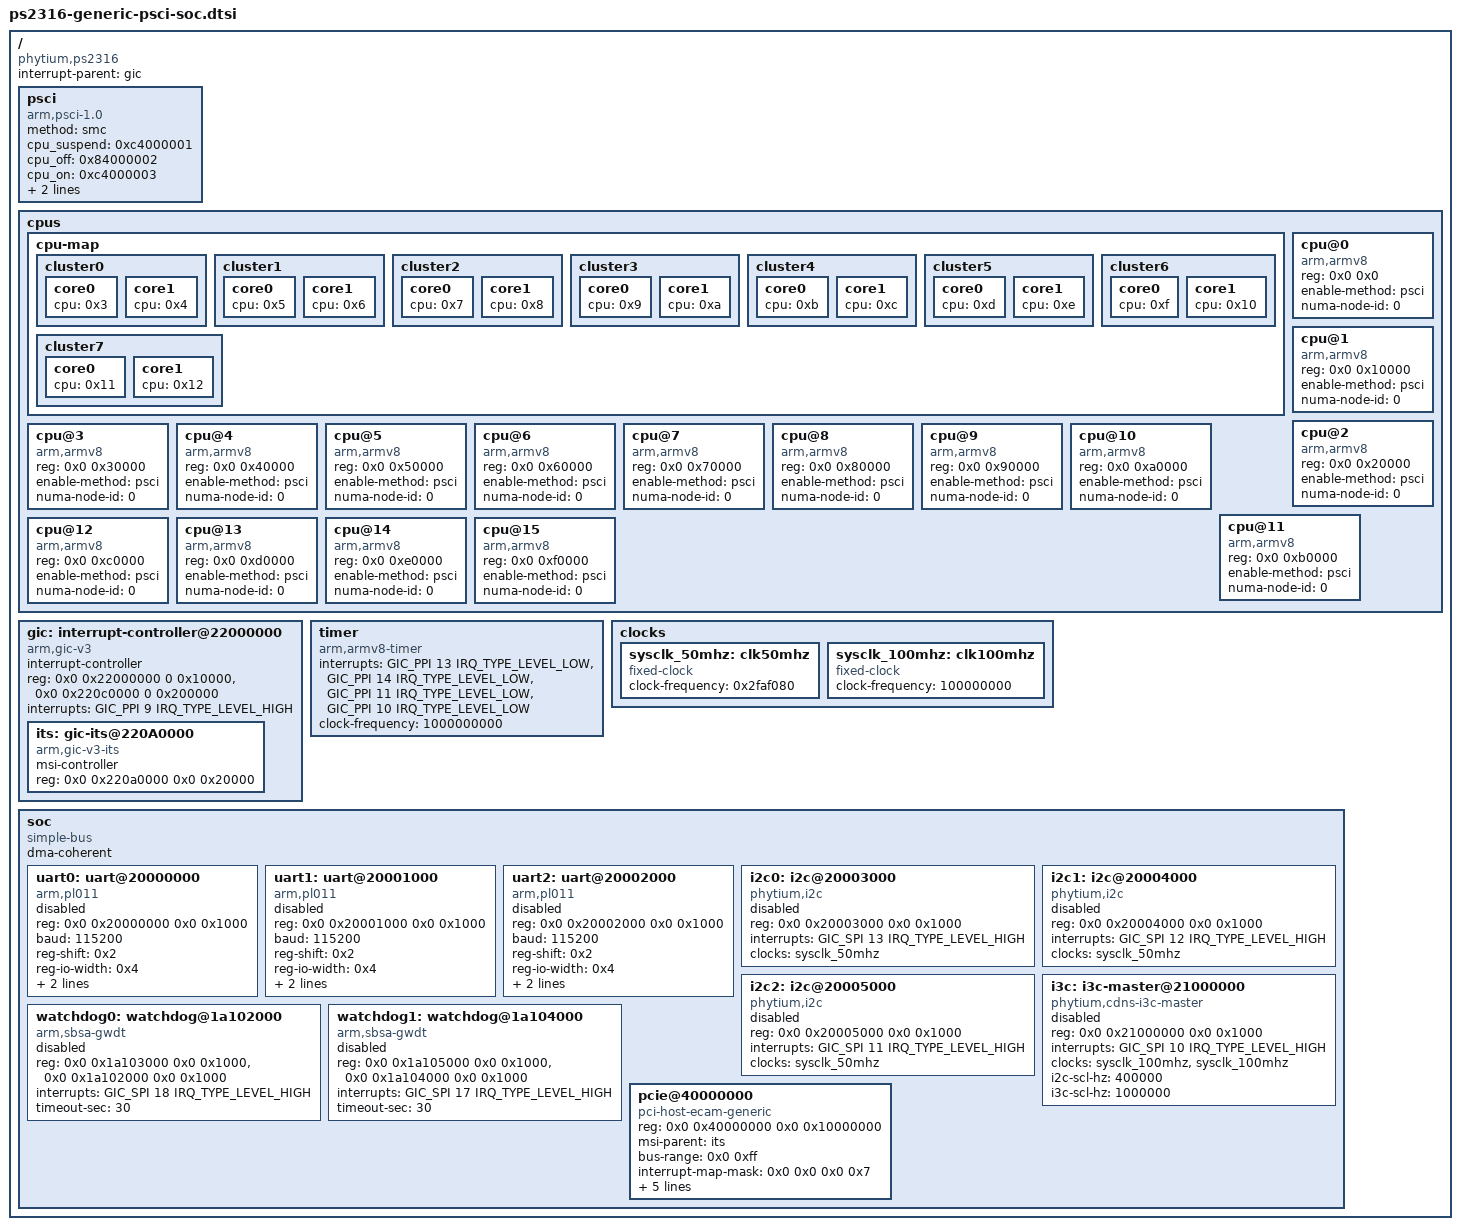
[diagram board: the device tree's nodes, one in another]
// SPDX-License-Identifier: GPL-2.0
/*
 * dts file for Phytium Ps2316 SoC
 *
 * Copyright (C) 2023, Phytium Technology Co., Ltd.
 */

#include <dt-bindings/interrupt-controller/arm-gic.h>

/ {
	compatible = "phytium,ps2316";
	interrupt-parent = <&gic>;
	#address-cells = <2>;
	#size-cells = <2>;

	psci {
		compatible   = "arm,psci-1.0";
		method       = "smc";
		cpu_suspend  = <0xc4000001>;
		cpu_off      = <0x84000002>;
		cpu_on       = <0xc4000003>;
		sys_poweroff = <0x84000008>;
		sys_reset    = <0x84000009>;
	};

	cpus {
		#address-cells = <0x2>;
		#size-cells = <0x0>;

		cpu-map {

			cluster0 {

				core0 {
					cpu = <0x3>;
				};

				core1 {
					cpu = <0x4>;
				};
			};

			cluster1 {

				core0 {
					cpu = <0x5>;
				};

				core1 {
					cpu = <0x6>;
				};
			};

			cluster2 {

				core0 {
					cpu = <0x7>;
				};

				core1 {
					cpu = <0x8>;
				};
			};

			cluster3 {

				core0 {
					cpu = <0x9>;
				};

				core1 {
					cpu = <0xa>;
				};
			};

			cluster4 {

				core0 {
					cpu = <0xb>;
				};

				core1 {
					cpu = <0xc>;
				};
			};

			cluster5 {

				core0 {
					cpu = <0xd>;
				};

				core1 {
					cpu = <0xe>;
				};
			};

			cluster6 {

				core0 {
					cpu = <0xf>;
				};

				core1 {
					cpu = <0x10>;
				};
			};

			cluster7 {

				core0 {
					cpu = <0x11>;
				};

				core1 {
					cpu = <0x12>;
				};
			};
		};

		cpu@0 {
			device_type = "cpu";
			compatible = "arm,armv8";
			reg = <0x0 0x0>;
			enable-method = "psci";
			numa-node-id = <0>;
			phandle = <0x3>;
		};

		cpu@1 {
			device_type = "cpu";
			compatible = "arm,armv8";
			reg = <0x0 0x10000>;
			enable-method = "psci";
			numa-node-id = <0>;
			phandle = <0x4>;
		};

		cpu@2 {
			device_type = "cpu";
			compatible = "arm,armv8";
			reg = <0x0 0x20000>;
			enable-method = "psci";
			numa-node-id = <0>;
			phandle = <0x5>;
		};

		cpu@3 {
			device_type = "cpu";
			compatible = "arm,armv8";
			reg = <0x0 0x30000>;
			enable-method = "psci";
			numa-node-id = <0>;
			phandle = <0x6>;
		};

		cpu@4 {
			device_type = "cpu";
			compatible = "arm,armv8";
			reg = <0x0 0x40000>;
			enable-method = "psci";
			numa-node-id = <0>;
			phandle = <0x7>;
		};

		cpu@5 {
			device_type = "cpu";
			compatible = "arm,armv8";
			reg = <0x0 0x50000>;
			enable-method = "psci";
			numa-node-id = <0>;
			phandle = <0x8>;
		};

		cpu@6 {
			device_type = "cpu";
			compatible = "arm,armv8";
			reg = <0x0 0x60000>;
			enable-method = "psci";
			numa-node-id = <0>;
			phandle = <0x9>;
		};

		cpu@7 {
			device_type = "cpu";
			compatible = "arm,armv8";
			reg = <0x0 0x70000>;
			enable-method = "psci";
			numa-node-id = <0>;
			phandle = <0xa>;
		};

		cpu@8 {
			device_type = "cpu";
			compatible = "arm,armv8";
			reg = <0x0 0x80000>;
			enable-method = "psci";
			numa-node-id = <0>;
			phandle = <0xb>;
		};

		cpu@9 {
			device_type = "cpu";
			compatible = "arm,armv8";
			reg = <0x0 0x90000>;
			enable-method = "psci";
			numa-node-id = <0>;
			phandle = <0xc>;
		};

		cpu@10 {
			device_type = "cpu";
			compatible = "arm,armv8";
			reg = <0x0 0xa0000>;
			enable-method = "psci";
			numa-node-id = <0>;
			phandle = <0xd>;
		};

		cpu@11 {
			device_type = "cpu";
			compatible = "arm,armv8";
			reg = <0x0 0xb0000>;
			enable-method = "psci";
			numa-node-id = <0>;
			phandle = <0xe>;
		};

		cpu@12 {
			device_type = "cpu";
			compatible = "arm,armv8";
			reg = <0x0 0xc0000>;
			enable-method = "psci";
			numa-node-id = <0>;
			phandle = <0xf>;
		};

		cpu@13 {
			device_type = "cpu";
			compatible = "arm,armv8";
			reg = <0x0 0xd0000>;
			enable-method = "psci";
			numa-node-id = <0>;
			phandle = <0x10>;
		};

		cpu@14 {
			device_type = "cpu";
			compatible = "arm,armv8";
			reg = <0x0 0xe0000>;
			enable-method = "psci";
			numa-node-id = <0>;
			phandle = <0x11>;
		};

		cpu@15 {
			device_type = "cpu";
			compatible = "arm,armv8";
			reg = <0x0 0xf0000>;
			enable-method = "psci";
			numa-node-id = <0>;
			phandle = <0x12>;
		};
	};

	gic: interrupt-controller@22000000 {
		compatible = "arm,gic-v3";
		#interrupt-cells = <0x3>;
		#address-cells = <0x2>;
		#size-cells = <0x2>;
		ranges;
		interrupt-controller;
		reg = <0x0 0x22000000 0 0x10000>,	/* GICD */
			<0x0 0x220c0000 0 0x200000>;	/* GICR */
		interrupts = <GIC_PPI 9 IRQ_TYPE_LEVEL_HIGH>;

		its: gic-its@220A0000 {
			compatible = "arm,gic-v3-its";
			msi-controller;
			reg = <0x0 0x220a0000 0x0 0x20000>;
		};

	};

	timer {
		compatible = "arm,armv8-timer";
		interrupts = <GIC_PPI 13 IRQ_TYPE_LEVEL_LOW>,
			     <GIC_PPI 14 IRQ_TYPE_LEVEL_LOW>,
			     <GIC_PPI 11 IRQ_TYPE_LEVEL_LOW>,
			     <GIC_PPI 10 IRQ_TYPE_LEVEL_LOW>;
		clock-frequency = <1000000000>;
	};

	clocks {
		#address-cells = <0x2>;
		#size-cells = <0x2>;
		ranges;

		sysclk_50mhz: clk50mhz {
			compatible = "fixed-clock";
			#clock-cells = <0x0>;
			clock-frequency = <0x2faf080>;
		};

		sysclk_100mhz: clk100mhz {
			compatible = "fixed-clock";
			#clock-cells = <0x0>;
			clock-frequency = <100000000>;
		};
	};

	soc {
		compatible = "simple-bus";
		#address-cells = <2>;
		#size-cells = <2>;
		dma-coherent;
		ranges;

		uart0: uart@20000000 {
			compatible = "arm,pl011", "arm,primecell";
			reg = <0x0 0x20000000 0x0 0x1000>;
			baud = <115200>;
			reg-shift = <0x2>;
			reg-io-width = <0x4>;
			interrupts = <GIC_SPI 16 IRQ_TYPE_LEVEL_HIGH>;
			clocks = <&sysclk_50mhz &sysclk_50mhz>;
			clock-names = "uartclk", "apb_pclk";
			status = "disabled";
		};

		uart1: uart@20001000 {
			compatible = "arm,pl011", "arm,primecell";
			reg = <0x0 0x20001000 0x0 0x1000>;
			baud = <115200>;
			reg-shift = <0x2>;
			reg-io-width = <0x4>;
			interrupts = <GIC_SPI 15 IRQ_TYPE_LEVEL_HIGH>;
			clocks = <&sysclk_50mhz &sysclk_50mhz>;
			clock-names = "uartclk", "apb_pclk";
			status = "disabled";
		};

		uart2: uart@20002000 {
			compatible = "arm,pl011", "arm,primecell";
			reg = <0x0 0x20002000 0x0 0x1000>;
			baud = <115200>;
			reg-shift = <0x2>;
			reg-io-width = <0x4>;
			interrupts = <GIC_SPI 14 IRQ_TYPE_LEVEL_HIGH>;
			clocks = <&sysclk_50mhz &sysclk_50mhz>;
			clock-names = "uartclk", "apb_pclk";
			status = "disabled";
		};

		i2c0: i2c@20003000 {
			compatible = "phytium,i2c";
			reg = <0x0 0x20003000 0x0 0x1000>;
			interrupts = <GIC_SPI 13 IRQ_TYPE_LEVEL_HIGH>;
			clocks = <&sysclk_50mhz>;
			#address-cells = <1>;
			#size-cells = <0>;
			status = "disabled";
		};

		i2c1: i2c@20004000 {
			compatible = "phytium,i2c";
			reg = <0x0 0x20004000 0x0 0x1000>;
			interrupts = <GIC_SPI 12 IRQ_TYPE_LEVEL_HIGH>;
			clocks = <&sysclk_50mhz>;
			#address-cells = <1>;
			#size-cells = <0>;
			status = "disabled";
		};

		i2c2: i2c@20005000 {
			compatible = "phytium,i2c";
			reg = <0x0 0x20005000 0x0 0x1000>;
			interrupts = <GIC_SPI 11 IRQ_TYPE_LEVEL_HIGH>;
			clocks = <&sysclk_50mhz>;
			#address-cells = <1>;
			#size-cells = <0>;
			status = "disabled";
		};

		i3c: i3c-master@21000000 {
			compatible = "phytium,cdns-i3c-master";
			reg = <0x0 0x21000000 0x0 0x1000>;
			interrupts = <GIC_SPI 10 IRQ_TYPE_LEVEL_HIGH>;
			clocks = <&sysclk_100mhz>, <&sysclk_100mhz>;
			clock-names = "pclk", "sysclk";
			#address-cells = <1>;
			#size-cells = <0>;
			i2c-scl-hz = <400000>;
			i3c-scl-hz = <1000000>;
			status = "disabled";
		};

		watchdog0: watchdog@1a102000 {
			compatible = "arm,sbsa-gwdt";
			reg = <0x0 0x1a103000 0x0 0x1000>,
				<0x0 0x1a102000 0x0 0x1000>;
			interrupts = <GIC_SPI 18 IRQ_TYPE_LEVEL_HIGH>;
			timeout-sec = <30>;
			status = "disabled";
		};

		watchdog1: watchdog@1a104000 {
			compatible = "arm,sbsa-gwdt";
			reg = <0x0 0x1a105000 0x0 0x1000>,
				<0x0 0x1a104000 0x0 0x1000>;
			interrupts = <GIC_SPI 17 IRQ_TYPE_LEVEL_HIGH>;
			timeout-sec = <30>;
			status = "disabled";
		};

		pcie@40000000 {
			compatible = "pci-host-ecam-generic";
			device_type = "pci";
			#address-cells = <0x3>;
			#size-cells = <0x2>;
			#interrupt-cells = <0x1>;
			reg = <0x0 0x40000000 0x0 0x10000000>;
			msi-parent = <&its>;
			bus-range = <0x0 0xff>;
			interrupt-map-mask = <0x0 0x0 0x0 0x7>;
			interrupt-map = <0x0 0x0 0x0 0x1 &gic 0x0 0x0 0x0 54 0x4>,
						<0x0 0x0 0x0 0x2 &gic 0x0 0x0 0x0 53 0x4>,
						<0x0 0x0 0x0 0x3 &gic 0x0 0x0 0x0 52 0x4>,
						<0x0 0x0 0x0 0x4 &gic 0x0 0x0 0x0 51 0x4>;
			ranges = <0x01000000 0x00 0x00000000 0x00  0x50000000 0x00  0x00F00000>,
				 <0x02000000 0x00 0x58000000 0x00  0x58000000 0x00  0x08000000>,
				 <0x43000000 0x400 0x00000000 0x400 0x00000000 0x100  0x00000000>;
			status = "okay";
		};
	};

};
